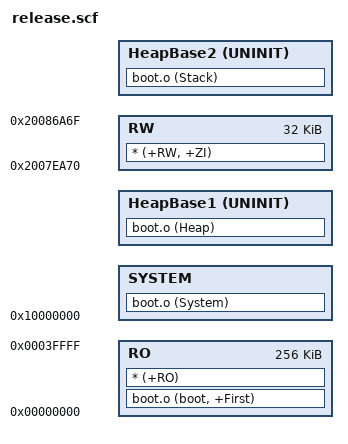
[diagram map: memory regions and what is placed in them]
;/******************************************************Copyright (c)**************************************************
;**                                              胆怯是阻止一切可能的根本缘由
;**
;**                                             E-Mail: ChinaFengliang@163.com
;**
;**---------File Information--------------------------------------------------------------------------------------------
;** File name:            release.scf
;** Last version:         V1.00
;** Descriptions:         分散加载文件.
;** Hardware platform:    LPC1766 
;** System information:   片内Flash空间 : 0x0000 0000 ~ 0x0004 0000 (共256K)
;**                       片内SRAM空间  : 0x1000 0000 ~ 0x1000 8000 (共32K)
;**                                       0x2007 C000 ~ 0x2008 4000 (共32K)
;**
;**--------------------------------------------------------------------------------------------------------------------
;** Created by:           Fengliang
;** Created date:         2010年9月4日  9:7:30
;** Version:              V1.00
;** Descriptions:         The original version
;**
;**--------------------------------------------------------------------------------------------------------------------
;** Modified by:		  
;** Modified date:		  
;** Version:
;** Descriptions:
;**
;*********************************************************************************************************************/

lpc1766 0x00000000
{
    ;/*
    ; * Execution RegionBase: Base: 0x00000000, Max: 0x00040000.
    ; */
    RO 0x00000000 0x00040000
    {
        boot.o (boot, +First)
        * (+RO)
    }
    
    SYSTEM 0x10000000
    {
        boot.o (System)
    }

    HeapBase1 +0 UNINIT
    {
        boot.o (Heap)
    }

    RW 0x2007EA70 0x00008000
    {
        * (+RW, +ZI)
    }

    HeapBase2 +0 UNINIT
    {
        boot.o (Stack)
    }
}

;/*********************************************************************************************************************
;                                                    END OF FILE
;*********************************************************************************************************************/


